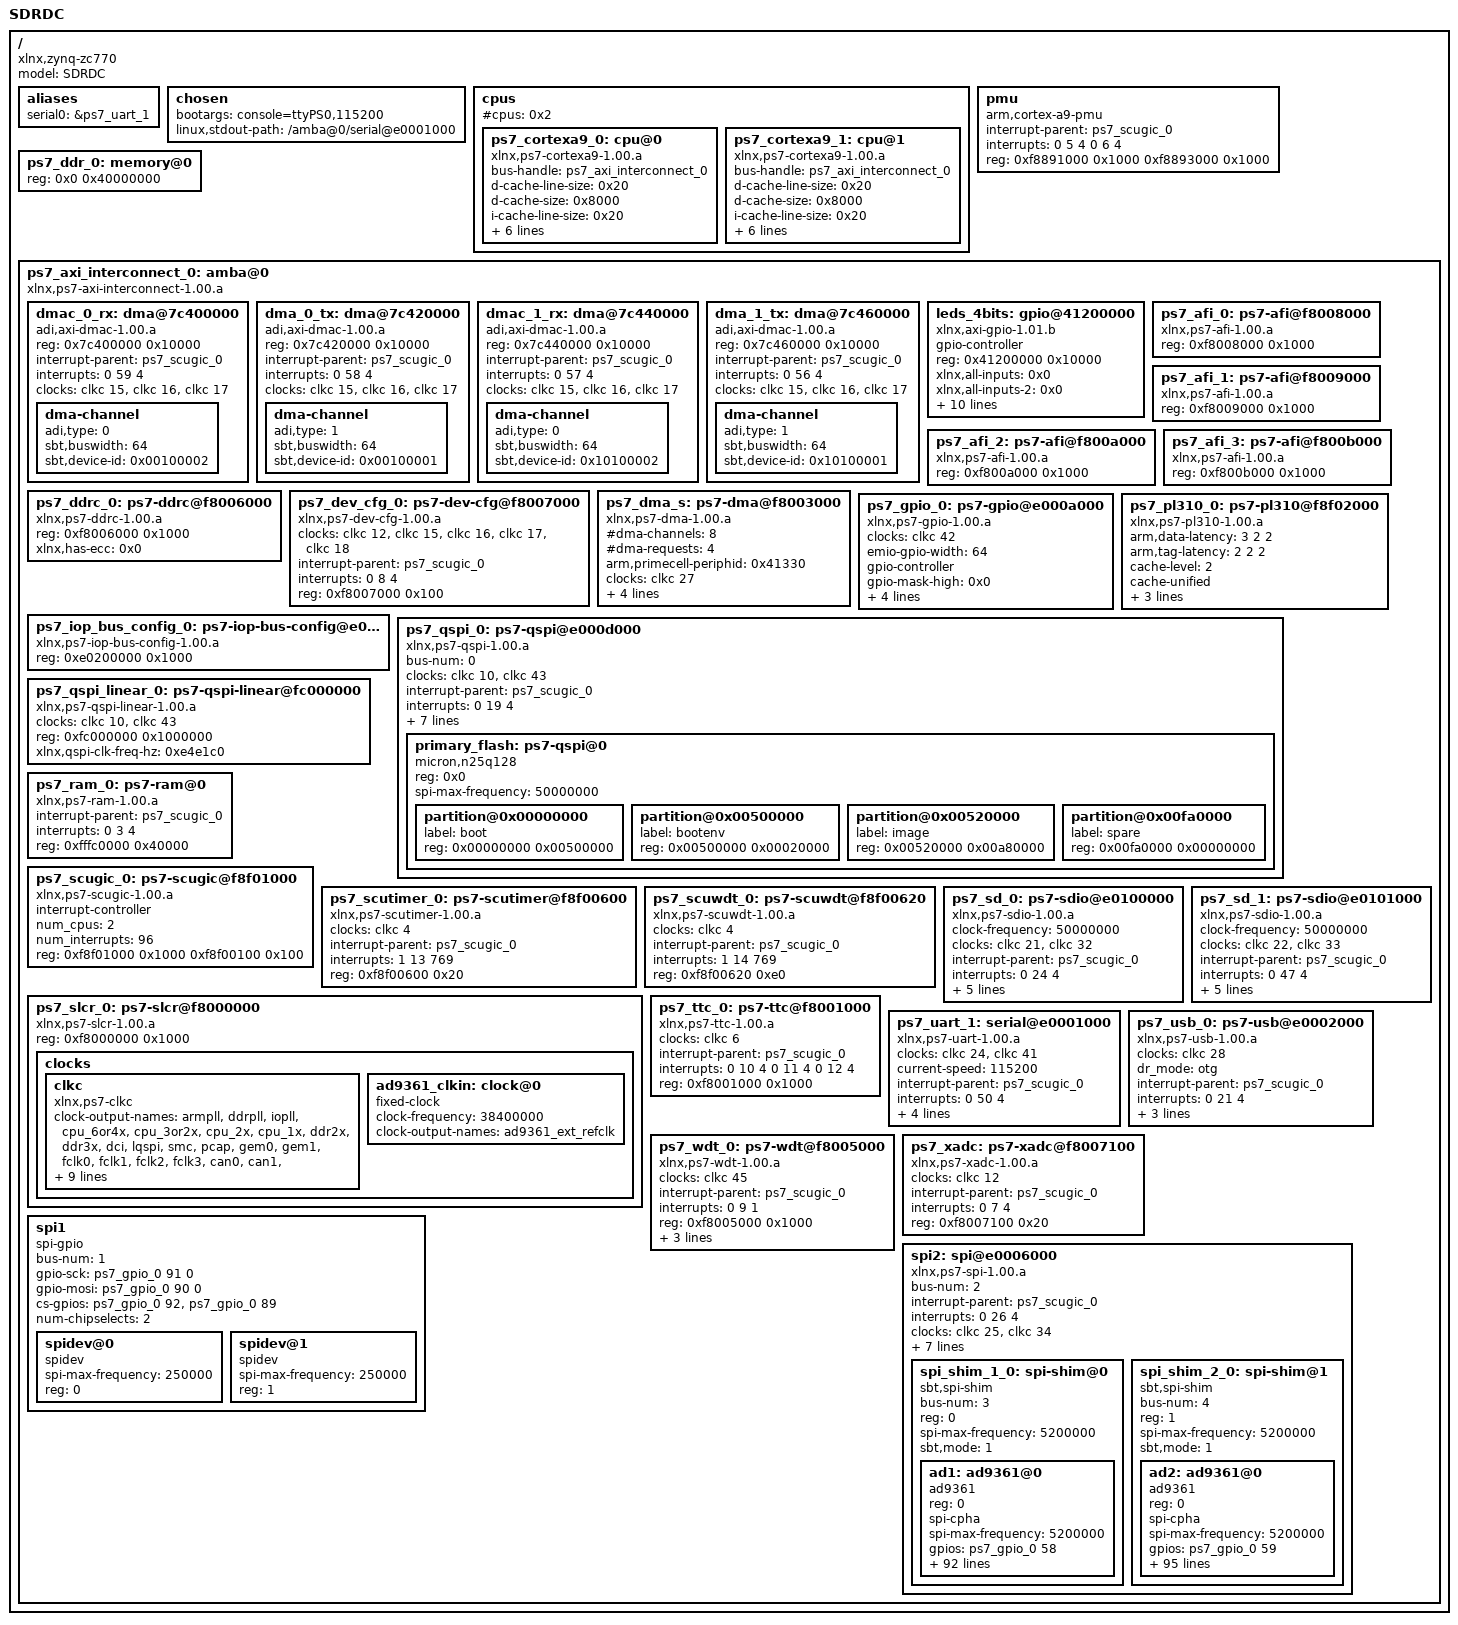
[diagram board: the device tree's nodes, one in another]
/*
 * Device Tree Generator version: 1.1
 *
 * (C) Copyright 2007-2012 Xilinx, Inc.
 * (C) Copyright 2007-2012 Michal Simek
 * (C) Copyright 2007-2012 PetaLogix Qld Pty Ltd
 *
 * Michal SIMEK <monstr@monstr.eu>
 *
 * This program is free software; you can redistribute it and/or
 * modify it under the terms of the GNU General Public License as
 * published by the Free Software Foundation; either version 2 of
 * the License, or (at your option) any later version.
 *
 * This program is distributed in the hope that it will be useful,
 * but WITHOUT ANY WARRANTY; without even the implied warranty of
 * MERCHANTABILITY or FITNESS FOR A PARTICULAR PURPOSE. See the
 * GNU General Public License for more details.
 *
 * You should have received a copy of the GNU General Public License
 * along with this program; if not, write to the Free Software
 * Foundation, Inc., 59 Temple Place, Suite 330, Boston,
 * MA 02111-1307 USA
 *
 * CAUTION: This file is automatically generated by libgen.
 * Version: Xilinx EDK 14.5 EDK_P.58f
 * Today is: Wednesday, the 27 of March, 2013; 04:30:06
 *
 * XPS project directory: Xilinx-ZC702-14.5
 */

/dts-v1/;
/ {
	#address-cells = <1>;
	#size-cells = <1>;
	compatible = "xlnx,zynq-zc770", "xlnx,zynq-7000";
	model = "SDRDC";
	aliases {
		serial0 = &ps7_uart_1;
	} ;
	chosen {
		bootargs = "console=ttyPS0,115200 ";
		linux,stdout-path = "/amba@0/serial@e0001000";
	} ;
	cpus {
		#address-cells = <1>;
		#cpus = <0x2>;
		#size-cells = <0>;
		ps7_cortexa9_0: cpu@0 {
			bus-handle = <&ps7_axi_interconnect_0>;
			compatible = "xlnx,ps7-cortexa9-1.00.a", "arm,cortex-a9";
			d-cache-line-size = <0x20>;
			d-cache-size = <0x8000>;
			device_type = "cpu";
			i-cache-line-size = <0x20>;
			i-cache-size = <0x8000>;
			model = "ps7_cortexa9,1.00.a";
			reg = <0>;
			xlnx,cpu-1x-clk-freq-hz = <0x69f6bca>;
			xlnx,cpu-clk-freq-hz = <0x27bc86c0>;
			interrupt-handle = <&ps7_scugic_0>;
		} ;
		ps7_cortexa9_1: cpu@1 {
			bus-handle = <&ps7_axi_interconnect_0>;
			compatible = "xlnx,ps7-cortexa9-1.00.a", "arm,cortex-a9";
			d-cache-line-size = <0x20>;
			d-cache-size = <0x8000>;
			device_type = "cpu";
			i-cache-line-size = <0x20>;
			i-cache-size = <0x8000>;
			model = "ps7_cortexa9,1.00.a";
			reg = <1>;
			xlnx,cpu-1x-clk-freq-hz = <0x69f6bca>;
			xlnx,cpu-clk-freq-hz = <0x27bc86c0>;
			interrupt-handle = <&ps7_scugic_0>;
		} ;
	} ;
	pmu {
		compatible = "arm,cortex-a9-pmu";
		interrupt-parent = <&ps7_scugic_0>;
		interrupts = < 0 5 4 0 6 4 >;
		reg = < 0xf8891000 0x1000 0xf8893000 0x1000 >;
		reg-names = "cpu0", "cpu1";
	} ;
	ps7_ddr_0: memory@0 {
		device_type = "memory";
		reg = < 0x0 0x40000000 >;
	} ;
	ps7_axi_interconnect_0: amba@0 {
		#address-cells = <1>;
		#size-cells = <1>;
		compatible = "xlnx,ps7-axi-interconnect-1.00.a", "simple-bus";
		ranges ;

		/* New DMAC from ADI git repo https://github.com/analogdevicesinc/linux.git */
		dmac_0_rx: dma@7c400000 {
			compatible = "adi,axi-dmac-1.00.a";
			reg = <0x7c400000 0x10000>;
			#dma-cells = <1>;
			interrupt-parent = <&ps7_scugic_0>;
			interrupts = <0 59 4>;
			clock-names = "fclk0", "fclk1", "fclk2";
			clocks = < &clkc 15 &clkc 16 &clkc 17 >;

			dma-channel {
				adi,type = <0>;
				sbt,buswidth = <64>;
				sbt,device-id = <0x00100002>;
			};
		};
		dma_0_tx: dma@7c420000 {
			compatible = "adi,axi-dmac-1.00.a";
			reg = <0x7c420000 0x10000>;
			#dma-cells = <1>;
			interrupt-parent = <&ps7_scugic_0>;
			interrupts = <0 58 4>;
			clock-names = "fclk0", "fclk1", "fclk2";
			clocks = < &clkc 15 &clkc 16 &clkc 17 >;

			dma-channel {
				adi,type = <1>;
				sbt,buswidth = <64>;
				sbt,device-id = <0x00100001>;
			};
		};
		dmac_1_rx: dma@7c440000 {
			compatible = "adi,axi-dmac-1.00.a";
			reg = <0x7c440000 0x10000>;
			#dma-cells = <1>;
			interrupt-parent = <&ps7_scugic_0>;
			interrupts = <0 57 4>;
			clock-names = "fclk0", "fclk1", "fclk2";
			clocks = < &clkc 15 &clkc 16 &clkc 17 >;

			dma-channel {
				adi,type = <0>;
				sbt,buswidth = <64>;
				sbt,device-id = <0x10100002>;
			};
		};
		dma_1_tx: dma@7c460000 {
			compatible = "adi,axi-dmac-1.00.a";
			reg = <0x7c460000 0x10000>;
			#dma-cells = <1>;
			interrupt-parent = <&ps7_scugic_0>;
			interrupts = <0 56 4>;
			clock-names = "fclk0", "fclk1", "fclk2";
			clocks = < &clkc 15 &clkc 16 &clkc 17 >;

			dma-channel {
				adi,type = <1>;
				sbt,buswidth = <64>;
				sbt,device-id = <0x10100001>;
			};
		};

		leds_4bits: gpio@41200000 {
			#gpio-cells = <2>;
			compatible = "xlnx,axi-gpio-1.01.b", "xlnx,xps-gpio-1.00.a";
			gpio-controller ;
			reg = < 0x41200000 0x10000 >;
			xlnx,all-inputs = <0x0>;
			xlnx,all-inputs-2 = <0x0>;
			xlnx,dout-default = <0x0>;
			xlnx,dout-default-2 = <0x0>;
			xlnx,family = "zynq";
			xlnx,gpio-width = <0x4>;
			xlnx,gpio2-width = <0x20>;
			xlnx,instance = "LEDs_4Bits";
			xlnx,interrupt-present = <0x0>;
			xlnx,is-dual = <0x0>;
			xlnx,tri-default = <0xffffffff>;
			xlnx,tri-default-2 = <0xffffffff>;
		} ;
		ps7_afi_0: ps7-afi@f8008000 {
			compatible = "xlnx,ps7-afi-1.00.a";
			reg = < 0xf8008000 0x1000 >;
		} ;
		ps7_afi_1: ps7-afi@f8009000 {
			compatible = "xlnx,ps7-afi-1.00.a";
			reg = < 0xf8009000 0x1000 >;
		} ;
		ps7_afi_2: ps7-afi@f800a000 {
			compatible = "xlnx,ps7-afi-1.00.a";
			reg = < 0xf800a000 0x1000 >;
		} ;
		ps7_afi_3: ps7-afi@f800b000 {
			compatible = "xlnx,ps7-afi-1.00.a";
			reg = < 0xf800b000 0x1000 >;
		} ;
		ps7_ddrc_0: ps7-ddrc@f8006000 {
			compatible = "xlnx,ps7-ddrc-1.00.a", "xlnx,ps7-ddrc";
			reg = < 0xf8006000 0x1000 >;
			xlnx,has-ecc = <0x0>;
		} ;
		ps7_dev_cfg_0: ps7-dev-cfg@f8007000 {
			clock-names = "ref_clk", "fclk0", "fclk1", "fclk2", "fclk3";
			clocks = <&clkc 12 &clkc 15 &clkc 16 &clkc 17 &clkc 18>;
			compatible = "xlnx,ps7-dev-cfg-1.00.a";
			interrupt-parent = <&ps7_scugic_0>;
			interrupts = < 0 8 4 >;
			reg = < 0xf8007000 0x100 >;
		} ;
		ps7_dma_s: ps7-dma@f8003000 {
			#dma-cells = <1>;
			#dma-channels = <8>;
			#dma-requests = <4>;
			arm,primecell-periphid = <0x41330>;
			clock-names = "apb_pclk";
			clocks = <&clkc 27>;
			compatible = "xlnx,ps7-dma-1.00.a", "arm,primecell", "arm,pl330";
			interrupt-names = "abort", "dma0", "dma1", "dma2", "dma3",
				"dma4", "dma5", "dma6", "dma7";
			interrupt-parent = <&ps7_scugic_0>;
			interrupts = < 0 13 4 0 14 4 0 15 4 0 16 4 0 17 4 0 40 4 0 41 4 0 42 4 0 43 4 >;
			reg = < 0xf8003000 0x1000 >;
		} ;
		ps7_gpio_0: ps7-gpio@e000a000 {
			#gpio-cells = <2>;
			clocks = <&clkc 42>;
			compatible = "xlnx,ps7-gpio-1.00.a";
			emio-gpio-width = <64>;
			gpio-controller ;
			gpio-mask-high = <0x0>;
			gpio-mask-low = <0x5600>;
			interrupt-parent = <&ps7_scugic_0>;
			interrupts = < 0 20 4 >;
			reg = < 0xe000a000 0x1000 >;
		} ;
		ps7_iop_bus_config_0: ps7-iop-bus-config@e0200000 {
			compatible = "xlnx,ps7-iop-bus-config-1.00.a";
			reg = < 0xe0200000 0x1000 >;
		} ;
		ps7_pl310_0: ps7-pl310@f8f02000 {
			arm,data-latency = < 3 2 2 >;
			arm,tag-latency = < 2 2 2 >;
			cache-level = < 2 >;
			cache-unified ;
			compatible = "xlnx,ps7-pl310-1.00.a", "arm,pl310-cache";
			interrupt-parent = <&ps7_scugic_0>;
			interrupts = < 0 2 4 >;
			reg = < 0xf8f02000 0x1000 >;
		} ;
		ps7_qspi_0: ps7-qspi@e000d000 {
			#address-cells = <1>;
			#size-cells = <0>;
			bus-num = <0>;
			clock-names = "ref_clk", "aper_clk";
			clocks = <&clkc 10 &clkc 43>;
			compatible = "xlnx,ps7-qspi-1.00.a";
			interrupt-parent = <&ps7_scugic_0>;
			interrupts = < 0 19 4 >;
			is-dual = <0>;
			num-chip-select = <1>;
			reg = < 0xe000d000 0x1000 >;
			speed-hz = <200000000>;
			xlnx,fb-clk = <0x1>;
			xlnx,qspi-clk-freq-hz = <0xbebc200>;
			xlnx,qspi-mode = <0x0>;
			primary_flash: ps7-qspi@0 {
				#address-cells = <1>;
				#size-cells = <1>;
				reg = < 0x0 >;
				spi-max-frequency = <50000000>;
				compatible = "micron,n25q128";
				partition@0x00000000 {
					label = "boot";
					reg = <0x00000000 0x00500000>;
				};
				partition@0x00500000 {
					label = "bootenv";
					reg = <0x00500000 0x00020000>;
				};
				partition@0x00520000 {
					label = "image";
					reg = <0x00520000 0x00a80000>;
				};
				partition@0x00fa0000 {
					label = "spare";
					reg = <0x00fa0000 0x00000000>;
				};
			} ;
		} ;
		ps7_qspi_linear_0: ps7-qspi-linear@fc000000 {
			clock-names = "ref_clk", "aper_clk";
			clocks = <&clkc 10 &clkc 43>;
			compatible = "xlnx,ps7-qspi-linear-1.00.a";
			reg = < 0xfc000000 0x1000000 >;
			xlnx,qspi-clk-freq-hz = <0xe4e1c0>;
		} ;
		ps7_ram_0: ps7-ram@0 {
			compatible = "xlnx,ps7-ram-1.00.a", "xlnx,ps7-ocm";
			interrupt-parent = <&ps7_scugic_0>;
			interrupts = < 0 3 4 >;
			reg = < 0xfffc0000 0x40000 >;
		} ;
		ps7_scugic_0: ps7-scugic@f8f01000 {
			#address-cells = < 2 >;
			#interrupt-cells = < 3 >;
			#size-cells = < 1 >;
			compatible = "xlnx,ps7-scugic-1.00.a", "arm,cortex-a9-gic", "arm,gic";
			interrupt-controller ;
			linux,phandle = < 0x1 >;
			phandle = < 0x1 >;
			num_cpus = <2>;
			num_interrupts = <96>;
			reg = < 0xf8f01000 0x1000 0xf8f00100 0x100 >;
		} ;
		ps7_scutimer_0: ps7-scutimer@f8f00600 {
			clocks = <&clkc 4>;
			compatible = "xlnx,ps7-scutimer-1.00.a", "arm,cortex-a9-twd-timer";
			interrupt-parent = <&ps7_scugic_0>;
			interrupts = < 1 13 769 >;
			reg = < 0xf8f00600 0x20 >;
		} ;
		ps7_scuwdt_0: ps7-scuwdt@f8f00620 {
			clocks = <&clkc 4>;
			compatible = "xlnx,ps7-scuwdt-1.00.a";
			device_type = "watchdog";
			interrupt-parent = <&ps7_scugic_0>;
			interrupts = < 1 14 769 >;
			reg = < 0xf8f00620 0xe0 >;
		} ;
		ps7_sd_0: ps7-sdio@e0100000 {
			clock-frequency = <50000000>;
			clock-names = "clk_xin", "clk_ahb";
			clocks = <&clkc 21 &clkc 32>;
			compatible = "xlnx,ps7-sdio-1.00.a", "generic-sdhci";
			interrupt-parent = <&ps7_scugic_0>;
			interrupts = < 0 24 4 >;
			reg = < 0xe0100000 0x1000 >;
			xlnx,has-cd = <0x0>;
			xlnx,has-power = <0x0>;
			xlnx,has-wp = <0x0>;
			xlnx,sdio-clk-freq-hz = <0x02FAF080>;
		} ;
		ps7_sd_1: ps7-sdio@e0101000 {
			clock-frequency = <50000000>;
			clock-names = "clk_xin", "clk_ahb";
			clocks = <&clkc 22 &clkc 33>;
			compatible = "xlnx,ps7-sdio-1.00.a", "generic-sdhci";
			interrupt-parent = <&ps7_scugic_0>;
			interrupts = < 0 47 4 >;
			reg = < 0xe0101000 0x1000 >;
			xlnx,has-cd = <0x0>;
			xlnx,has-power = <0x0>;
			xlnx,has-wp = <0x0>;
			xlnx,sdio-clk-freq-hz = <0x02FAF080>;
		} ;
		ps7_slcr_0: ps7-slcr@f8000000 {
			compatible = "xlnx,ps7-slcr-1.00.a", "xlnx,zynq-slcr";
			reg = < 0xf8000000 0x1000 >;
			clocks {
				#address-cells = <1>;
				#size-cells = <0>;
				clkc: clkc {
					#clock-cells = <1>;
					clock-output-names =
						"armpll",      /*  0 */
						"ddrpll",      /*  1 */
						"iopll",       /*  2 */
						"cpu_6or4x",   /*  3 */
						"cpu_3or2x",   /*  4 */
						"cpu_2x",      /*  5 */
						"cpu_1x",      /*  6 */
						"ddr2x",       /*  7 */
						"ddr3x",       /*  8 */
						"dci",         /*  9 */
						"lqspi",       /* 10 */
						"smc",         /* 11 */
						"pcap",        /* 12 */
						"gem0",        /* 13 */
						"gem1",        /* 14 */
						"fclk0",       /* 15 */
						"fclk1",       /* 16 */
						"fclk2",       /* 17 */
						"fclk3",       /* 18 */
						"can0",        /* 19 */
						"can1",        /* 20 */
						"sdio0",       /* 21 */
						"sdio1",       /* 22 */
						"uart0",       /* 23 */
						"uart1",       /* 24 */
						"spi0",        /* 25 */
						"spi1",        /* 26 */
						"dma",         /* 27 */
						"usb0_aper",   /* 28 */
						"usb1_aper",   /* 29 */
						"gem0_aper",   /* 30 */
						"gem1_aper",   /* 31 */
						"sdio0_aper",  /* 32 */
						"sdio1_aper",  /* 33 */
						"spi0_aper",   /* 34 */
						"spi1_aper",   /* 35 */
						"can0_aper",   /* 36 */
						"can1_aper",   /* 37 */
						"i2c0_aper",   /* 38 */
						"i2c1_aper",   /* 39 */
						"uart0_aper",  /* 40 */
						"uart1_aper",  /* 41 */
						"gpio_aper",   /* 42 */
						"lqspi_aper",  /* 43 */
						"smc_aper",    /* 44 */
						"swdt",        /* 45 */
						"dbg_trc",     /* 46 */
						"dbg_apb";     /* 47 */
					compatible = "xlnx,ps7-clkc";
					fclk-enable = <0xf>;
					ps-clk-frequency = <38400000>;
				} ;
				ad9361_clkin: clock@0 {
					#clock-cells = <0>;
					compatible = "fixed-clock";
					clock-frequency = <38400000>;
					clock-output-names = "ad9361_ext_refclk";
				};
			} ;
		} ;
		ps7_ttc_0: ps7-ttc@f8001000 {
			clocks = <&clkc 6>;
			compatible = "xlnx,ps7-ttc-1.00.a";
			interrupt-names = "ttc0", "ttc1", "ttc2";
			interrupt-parent = <&ps7_scugic_0>;
			interrupts = < 0 10 4 0 11 4 0 12 4 >;
			reg = < 0xf8001000 0x1000 >;
		} ;
		ps7_uart_1: serial@e0001000 {
			clock-names = "ref_clk", "aper_clk";
			clocks = <&clkc 24 &clkc 41>;
			compatible = "xlnx,ps7-uart-1.00.a", "xlnx,xuartps";
			current-speed = <115200>;
			device_type = "serial";
			interrupt-parent = <&ps7_scugic_0>;
			interrupts = < 0 50 4 >;
			port-number = <0>;
			reg = < 0xe0001000 0x1000 >;
			xlnx,has-modem = <0x0>;
			xlnx,uart-clk-freq-hz = <0x2faf080>;
		} ;
		ps7_usb_0: ps7-usb@e0002000 {
			clocks = <&clkc 28>;
			compatible = "xlnx,ps7-usb-1.00.a";
			dr_mode = "otg";
			interrupt-parent = <&ps7_scugic_0>;
			interrupts = < 0 21 4 >;
			phy_type = "ulpi";
			reg = < 0xe0002000 0x1000 >;
			xlnx,usb-reset = "MIO 7";
		} ;
		ps7_wdt_0: ps7-wdt@f8005000 {
			clocks = <&clkc 45>;
			compatible = "xlnx,ps7-wdt-1.00.a";
			device_type = "watchdog";
			interrupt-parent = <&ps7_scugic_0>;
			interrupts = < 0 9 1 >;
			reg = < 0xf8005000 0x1000 >;
			reset = <0>;
			timeout = <10>;
			xlnx,wdt-clk-freq-hz = <0x69f6bc8>;
		} ;
		ps7_xadc: ps7-xadc@f8007100 {
			clocks = <&clkc 12>;
			compatible = "xlnx,ps7-xadc-1.00.a";
			interrupt-parent = <&ps7_scugic_0>;
			interrupts = < 0 7 4 >;
			reg = < 0xf8007100 0x20 >;
		} ;

		spi1 {
			bus-num = <1>;
			compatible = "spi-gpio";
			#address-cells = <0x1>;
			ranges;

			gpio-sck  = < &ps7_gpio_0 91 0 >;
			gpio-mosi = < &ps7_gpio_0 90 0 >;
/*			gpio-miso = < &ps7_gpio_0 89 0 >; */
			cs-gpios  = <
				&ps7_gpio_0 92 0
				&ps7_gpio_0 89 0
			>;
			num-chipselects = <2>;

			spidev@0 {
				compatible = "spidev";
				spi-max-frequency = <250000>;
				reg = <0>;
			};
			spidev@1 {
				compatible = "spidev";
				spi-max-frequency = <250000>;
				reg = <1>;
			};
		};

		spi2: spi@e0006000 {
			bus-num = <2>;
			compatible = "xlnx,ps7-spi-1.00.a";
			interrupt-parent = <&ps7_scugic_0>;
			interrupts = <0 26 4>;
			clock-names = "ref_clk", "aper_clk";
			clocks = <&clkc 25>, <&clkc 34>;
			num-chip-select = <2>;
			reg = <0xe0006000 0x1000>;
			speed-hz = <166666666>;
			xlnx,has-ss0 = <0x1>;
			xlnx,has-ss1 = <0x1>;
			xlnx,has-ss2 = <0x0>;
			xlnx,spi-clk-freq-hz = <166666666>;
			#address-cells = <1>;
			#size-cells = <0>;

			spi_shim_1_0: spi-shim@0 {
				bus-num = <3>;
				compatible = "sbt,spi-shim", "spi-shim", "spi_shim";
				reg = <0>;
				spi-max-frequency = <5200000>;
				sbt,mode = <1>;

				/* Clients */
				ad1: ad9361@0 {
					#address-cells = <1>;
					#size-cells = <0>;
					#clock-cells = <1>;
					compatible = "ad9361";

					/* SPI Setup */
					reg = <0>;
					spi-cpha;
					spi-max-frequency = <5200000>;

					/* Reset: 58 (AD1), 59 (AD2)  */
					gpios = < &ps7_gpio_0 58 0 >;

					/* Enable: 104 (AD1), 111 (AD2) */
					/* TXNRX:  105 (AD1), 112 (AD2) */

					/* Clocks */
					clocks = <&ad9361_clkin 0>;
					clock-names = "ad9361_ext_refclk";
					clock-output-names = "rx_sampl_clk", "tx_sampl_clk";
					adi,clk-output-mode-select = <1>;

					//adi,debug-mode-enable;
					/* Digital Interface Control */

					adi,pp-tx-swap-enable;
					adi,pp-rx-swap-enable;
					adi,rx-frame-pulse-mode-enable;
					adi,lvds-mode-enable;
					adi,lvds-bias-mV = <225>;
					//adi,lvds-rx-onchip-termination-enable;
					adi,rx-data-delay = <11>;
					adi,tx-fb-clock-delay = <8>;
					adi,rx-data-clock-delay = <0>;
					adi,tx-data-delay = <0>;
					adi,full-port-enable;

					//adi,fdd-rx-rate-2tx-enable;

					adi,dcxo-coarse-and-fine-tune = <8 5920>;
					//adi,xo-disable-use-ext-refclk-enable;

					/* Mode Setup */
					adi,2rx-2tx-mode-enable;
					//adi,split-gain-table-mode-enable;

					/* Note: SDRDC DMA stack currently supports T2R2 mode only, regardless
					 * of how many channels are enabled.  leave this setting enabled if
					 * disabling adi,2rx-2tx-mode-enable above
					 */
					adi,2t2r-timing-enable;

					/* ENSM Mode */
					adi,frequency-division-duplex-mode-enable;
					//adi,ensm-pin-pulse-mode-enable;
					//adi,ensm-enable-txnrx-control-enable;


					/* adi,rx-rf-port-input-select:
					 * 0 = (RX1A_N &  RX1A_P) and (RX2A_N & RX2A_P) enabled; balanced
					 * 1 = (RX1B_N &  RX1B_P) and (RX2B_N & RX2B_P) enabled; balanced
					 * 2 = (RX1C_N &  RX1C_P) and (RX2C_N & RX2C_P) enabled; balanced
					 *
					 * 3 = RX1A_N and RX2A_N enabled; unbalanced
					 * 4 = RX1A_P and RX2A_P enabled; unbalanced
					 * 5 = RX1B_N and RX2B_N enabled; unbalanced
					 * 6 = RX1B_P and RX2B_P enabled; unbalanced
					 * 7 = RX1C_N and RX2C_N enabled; unbalanced
					 * 8 = RX1C_P and RX2C_P enabled; unbalanced
					 */

					adi,rx-rf-port-input-select = <0>; /* (RX1A_N &  RX1A_P) and (RX2A_N & RX2A_P) enabled; balanced */

					/* adi,tx-rf-port-input-select:
					 * 0	TX1A, TX2A
					 * 1	TX1B, TX2B
					 */

					adi,tx-rf-port-input-select = <0>; /* TX1A, TX2A */
					//adi,update-tx-gain-in-alert-enable;
					adi,tx-attenuation-mdB = <10000>;

					adi,rf-rx-bandwidth-hz = <3500000>;
					adi,rf-tx-bandwidth-hz = <3500000>;
					adi,rx-synthesizer-frequency-hz = /bits/ 64 <2400000000>;
					adi,tx-synthesizer-frequency-hz = /bits/ 64 <2400000000>;

					/*                              BBPLL        ADC        R2CLK     R1CLK     CLKRF    RSAMPL  */
					adi,rx-path-clock-frequencies = <1024000000  128000000  32000000  16000000  4000000  4000000>;
					/*                              BBPLL        DAC        T2CLK     T1CLK     CLKTF    TSAMPL  */
					adi,tx-path-clock-frequencies = <1024000000  128000000  32000000  16000000  4000000  4000000>;

					/* Gain Control */

					/* adi,gc-rx[1|2]-mode:
					 * 0 = RF_GAIN_MGC
					 * 1 = RF_GAIN_FASTATTACK_AGC
					 * 2 = RF_GAIN_SLOWATTACK_AGC
					 * 3 = RF_GAIN_HYBRID_AGC
					 */

					adi,gc-rx1-mode = <1>;
					adi,gc-rx2-mode = <1>;
					adi,gc-adc-ovr-sample-size = <4>; /* sum 4 samples */
					adi,gc-adc-small-overload-thresh = <47>; /* sum of squares */
					adi,gc-adc-large-overload-thresh = <58>; /* sum of squares */
					adi,gc-lmt-overload-high-thresh = <800>; /* mV */
					adi,gc-lmt-overload-low-thresh = <704>; /* mV */
					adi,gc-dec-pow-measurement-duration = <8192>; /* 0..524288 Samples */
					adi,gc-low-power-thresh = <24>; /* 0..-64 dBFS vals are set pos */
					//adi,gc-dig-gain-enable;
					//adi,gc-max-dig-gain = <15>;

					/* Manual Gain Control Setup */

					//adi,mgc-rx1-ctrl-inp-enable; /* uncomment to use ctrl inputs */
					//adi,mgc-rx2-ctrl-inp-enable; /* uncomment to use ctrl inputs */
					adi,mgc-inc-gain-step = <2>;
					adi,mgc-dec-gain-step = <2>;

					/* adi,mgc-split-table-ctrl-inp-gain-mode:
					 * (relevant if adi,split-gain-table-mode-enable is set)
					 * 0 = AGC determine this
					 * 1 = only in LPF
					 * 2 = only in LMT
					 */

					adi,mgc-split-table-ctrl-inp-gain-mode = <0>;

					/* Automatic Gain Control Setup */

					adi,agc-attack-delay-extra-margin-us= <1>; /* us */
					adi,agc-outer-thresh-high = <5>; /* -dBFS */
					adi,agc-outer-thresh-high-dec-steps = <2>; /* 0..15 */
					adi,agc-inner-thresh-high = <10>; /* -dBFS */
					adi,agc-inner-thresh-high-dec-steps = <1>; /* 0..7 */
					adi,agc-inner-thresh-low = <12>; /* -dBFS */
					adi,agc-inner-thresh-low-inc-steps = <1>; /* 0..7 */
					adi,agc-outer-thresh-low = <18>; /* -dBFS */
					adi,agc-outer-thresh-low-inc-steps = <2>; /* 0..15 */

					adi,agc-adc-small-overload-exceed-counter = <10>; /* 0..15 */
					adi,agc-adc-large-overload-exceed-counter = <10>; /* 0..15 */
					adi,agc-adc-large-overload-inc-steps = <2>; /* 0..15 */
					//adi,agc-adc-lmt-small-overload-prevent-gain-inc-enable;
					adi,agc-lmt-overload-large-exceed-counter = <10>; /* 0..15 */
					adi,agc-lmt-overload-small-exceed-counter = <10>; /* 0..15 */
					adi,agc-lmt-overload-large-inc-steps = <2>; /* 0..7 */
					//adi,agc-dig-saturation-exceed-counter = <3>; /* 0..15 */
					//adi,agc-dig-gain-step-size = <4>; /* 1..8 */

					//adi,agc-sync-for-gain-counter-enable;
					adi,agc-gain-update-interval-us = <1000>;  /* 1ms */
					//adi,agc-immed-gain-change-if-large-adc-overload-enable;
					//adi,agc-immed-gain-change-if-large-lmt-overload-enable;

					/* Fast AGC */

					//adi,fagc-allow-agc-gain-increase-enable;
					adi,fagc-lp-thresh-increment-steps = <1>;
					adi,fagc-lp-thresh-increment-time = <5>;

					adi,fagc-energy-lost-stronger-sig-gain-lock-exit-cnt = <8>;
					adi,fagc-final-overrange-count = <3>;
					//adi,fagc-gain-increase-after-gain-lock-enable;
					adi,fagc-gain-index-type-after-exit-rx-mode = <0>;
					adi,fagc-lmt-final-settling-steps = <1>;
					adi,fagc-lock-level = <10>;
					adi,fagc-lock-level-gain-increase-upper-limit = <5>;
					adi,fagc-lock-level-lmt-gain-increase-enable;

					adi,fagc-lpf-final-settling-steps = <1>;
					adi,fagc-optimized-gain-offset = <5>;
					adi,fagc-power-measurement-duration-in-state5 = <64>;
					adi,fagc-rst-gla-engergy-lost-goto-optim-gain-enable;
					adi,fagc-rst-gla-engergy-lost-sig-thresh-below-ll = <10>;
					adi,fagc-rst-gla-engergy-lost-sig-thresh-exceeded-enable;
					adi,fagc-rst-gla-if-en-agc-pulled-high-mode = <0>;
					adi,fagc-rst-gla-large-adc-overload-enable;
					adi,fagc-rst-gla-large-lmt-overload-enable;
					adi,fagc-rst-gla-stronger-sig-thresh-above-ll = <10>;
					adi,fagc-rst-gla-stronger-sig-thresh-exceeded-enable;
					adi,fagc-state-wait-time-ns = <260>;
					adi,fagc-use-last-lock-level-for-set-gain-enable;

					/* RSSI */

					/* adi,rssi-restart-mode:
					 * 0 = AGC_IN_FAST_ATTACK_MODE_LOCKS_THE_GAIN,
					 * 1 = EN_AGC_PIN_IS_PULLED_HIGH,
					 * 2 = ENTERS_RX_MODE,
					 * 3 = GAIN_CHANGE_OCCURS,
					 * 4 = SPI_WRITE_TO_REGISTER,
					 * 5 = GAIN_CHANGE_OCCURS_OR_EN_AGC_PIN_PULLED_HIGH,
					 */
					adi,rssi-restart-mode = <3>;
					//adi,rssi-unit-is-rx-samples-enable;
					adi,rssi-delay = <1>; /* 1us */
					adi,rssi-wait = <1>; /* 1us */
					adi,rssi-duration = <1000>; /* 1ms */

					/* Control Outputs */
					adi,ctrl-outs-index = <0>;
					adi,ctrl-outs-enable-mask = <0xFF>;

					/* AuxADC Temp Sense Control */

					adi,temp-sense-measurement-interval-ms = <1000>;
					adi,temp-sense-offset-signed = <0xCE>;
					adi,temp-sense-periodic-measurement-enable;

				}; // ad1

			}; // spi_shim_1_0

			spi_shim_2_0: spi-shim@1 {
				bus-num = <4>;
				compatible = "sbt,spi-shim", "spi-shim", "spi_shim";
				reg = <1>;
				spi-max-frequency = <5200000>;
				sbt,mode = <1>;

				/* clients */
				ad2: ad9361@0 {
					#address-cells = <1>;
					#size-cells = <0>;
					#clock-cells = <1>;
					compatible = "ad9361";

					/* SPI Setup */
					reg = <0>;
					spi-cpha;
					spi-max-frequency = <5200000>;

					/* Reset: 58 (AD1), 59 (AD2)  */
					gpios = < &ps7_gpio_0 59 0 >;

					/* Enable: 104 (AD1), 111 (AD2) */
					/* TXNRX:  105 (AD1), 112 (AD2) */

					/* Clocks */
					clocks = <&ad9361_clkin 0>;
					clock-names = "ad9361_ext_refclk";
					clock-output-names = "rx_sampl_clk", "tx_sampl_clk";
					adi,clk-output-mode-select = <1>;

					//adi,debug-mode-enable;
					/* Digital Interface Control */

					adi,pp-tx-swap-enable;
					adi,pp-rx-swap-enable;
					adi,rx-frame-pulse-mode-enable;
					adi,lvds-mode-enable;
					adi,lvds-bias-mV = <225>;
					//adi,lvds-rx-onchip-termination-enable;
					adi,rx-data-delay = <11>;
					adi,tx-fb-clock-delay = <8>;
					adi,rx-data-clock-delay = <0>;
					adi,tx-data-delay = <0>;
					adi,full-port-enable;

					//adi,fdd-rx-rate-2tx-enable;

					adi,dcxo-coarse-and-fine-tune = <8 5920>;
					//adi,xo-disable-use-ext-refclk-enable;

					/* Mode Setup */
					adi,2rx-2tx-mode-enable;
					//adi,split-gain-table-mode-enable;

					/* Note: SDRDC DMA stack currently supports T2R2 mode only, regardless
					 * of how many channels are enabled.  leave this setting enabled if
					 * disabling adi,2rx-2tx-mode-enable above
					 */
					adi,2t2r-timing-enable;

					/* ENSM Mode */
					adi,frequency-division-duplex-mode-enable;
					//adi,ensm-pin-pulse-mode-enable;
					//adi,ensm-enable-txnrx-control-enable;


					/* adi,rx-rf-port-input-select:
					 * 0 = (RX1A_N &  RX1A_P) and (RX2A_N & RX2A_P) enabled; balanced
					 * 1 = (RX1B_N &  RX1B_P) and (RX2B_N & RX2B_P) enabled; balanced
					 * 2 = (RX1C_N &  RX1C_P) and (RX2C_N & RX2C_P) enabled; balanced
					 *
					 * 3 = RX1A_N and RX2A_N enabled; unbalanced
					 * 4 = RX1A_P and RX2A_P enabled; unbalanced
					 * 5 = RX1B_N and RX2B_N enabled; unbalanced
					 * 6 = RX1B_P and RX2B_P enabled; unbalanced
					 * 7 = RX1C_N and RX2C_N enabled; unbalanced
					 * 8 = RX1C_P and RX2C_P enabled; unbalanced
					 */

					adi,rx-rf-port-input-select = <0>; /* (RX1A_N &  RX1A_P) and (RX2A_N & RX2A_P) enabled; balanced */

					/* adi,tx-rf-port-input-select:
					 * 0	TX1A, TX2A
					 * 1	TX1B, TX2B
					 */

					adi,tx-rf-port-input-select = <0>; /* TX1A, TX2A */
					//adi,update-tx-gain-in-alert-enable;
					adi,tx-attenuation-mdB = <10000>;

					adi,rf-rx-bandwidth-hz = <3500000>;
					adi,rf-tx-bandwidth-hz = <3500000>;
					adi,rx-synthesizer-frequency-hz = /bits/ 64 <2400000000>;
					adi,tx-synthesizer-frequency-hz = /bits/ 64 <2400000000>;

					/*                              BBPLL        ADC        R2CLK     R1CLK     CLKRF    RSAMPL  */
					adi,rx-path-clock-frequencies = <1024000000  128000000  32000000  16000000  4000000  4000000>;
					/*                              BBPLL        DAC        T2CLK     T1CLK     CLKTF    TSAMPL  */
					adi,tx-path-clock-frequencies = <1024000000  128000000  32000000  16000000  4000000  4000000>;

					/* Gain Control */

					/* adi,gc-rx[1|2]-mode:
					 * 0 = RF_GAIN_MGC
					 * 1 = RF_GAIN_FASTATTACK_AGC
					 * 2 = RF_GAIN_SLOWATTACK_AGC
					 * 3 = RF_GAIN_HYBRID_AGC
					 */

					adi,gc-rx1-mode = <1>;
					adi,gc-rx2-mode = <1>;
					adi,gc-adc-ovr-sample-size = <4>; /* sum 4 samples */
					adi,gc-adc-small-overload-thresh = <47>; /* sum of squares */
					adi,gc-adc-large-overload-thresh = <58>; /* sum of squares */
					adi,gc-lmt-overload-high-thresh = <800>; /* mV */
					adi,gc-lmt-overload-low-thresh = <704>; /* mV */
					adi,gc-dec-pow-measurement-duration = <8192>; /* 0..524288 Samples */
					adi,gc-low-power-thresh = <24>; /* 0..-64 dBFS vals are set pos */
					//adi,gc-dig-gain-enable;
					//adi,gc-max-dig-gain = <15>;

					/* Manual Gain Control Setup */

					//adi,mgc-rx1-ctrl-inp-enable; /* uncomment to use ctrl inputs */
					//adi,mgc-rx2-ctrl-inp-enable; /* uncomment to use ctrl inputs */
					adi,mgc-inc-gain-step = <2>;
					adi,mgc-dec-gain-step = <2>;

					/* adi,mgc-split-table-ctrl-inp-gain-mode:
					 * (relevant if adi,split-gain-table-mode-enable is set)
					 * 0 = AGC determine this
					 * 1 = only in LPF
					 * 2 = only in LMT
					 */

					adi,mgc-split-table-ctrl-inp-gain-mode = <0>;

					/* Automatic Gain Control Setup */

					adi,agc-attack-delay-extra-margin-us= <1>; /* us */
					adi,agc-outer-thresh-high = <5>; /* -dBFS */
					adi,agc-outer-thresh-high-dec-steps = <2>; /* 0..15 */
					adi,agc-inner-thresh-high = <10>; /* -dBFS */
					adi,agc-inner-thresh-high-dec-steps = <1>; /* 0..7 */
					adi,agc-inner-thresh-low = <12>; /* -dBFS */
					adi,agc-inner-thresh-low-inc-steps = <1>; /* 0..7 */
					adi,agc-outer-thresh-low = <18>; /* -dBFS */
					adi,agc-outer-thresh-low-inc-steps = <2>; /* 0..15 */

					adi,agc-adc-small-overload-exceed-counter = <10>; /* 0..15 */
					adi,agc-adc-large-overload-exceed-counter = <10>; /* 0..15 */
					adi,agc-adc-large-overload-inc-steps = <2>; /* 0..15 */
					//adi,agc-adc-lmt-small-overload-prevent-gain-inc-enable;
					adi,agc-lmt-overload-large-exceed-counter = <10>; /* 0..15 */
					adi,agc-lmt-overload-small-exceed-counter = <10>; /* 0..15 */
					adi,agc-lmt-overload-large-inc-steps = <2>; /* 0..7 */
					//adi,agc-dig-saturation-exceed-counter = <3>; /* 0..15 */
					//adi,agc-dig-gain-step-size = <4>; /* 1..8 */

					//adi,agc-sync-for-gain-counter-enable;
					adi,agc-gain-update-interval-us = <1000>;  /* 1ms */
					//adi,agc-immed-gain-change-if-large-adc-overload-enable;
					//adi,agc-immed-gain-change-if-large-lmt-overload-enable;

					/* Fast AGC */

					//adi,fagc-allow-agc-gain-increase-enable;
					adi,fagc-lp-thresh-increment-steps = <1>;
					adi,fagc-lp-thresh-increment-time = <5>;

					adi,fagc-energy-lost-stronger-sig-gain-lock-exit-cnt = <8>;
					adi,fagc-final-overrange-count = <3>;
					//adi,fagc-gain-increase-after-gain-lock-enable;
					adi,fagc-gain-index-type-after-exit-rx-mode = <0>;
					adi,fagc-lmt-final-settling-steps = <1>;
					adi,fagc-lock-level = <10>;
					adi,fagc-lock-level-gain-increase-upper-limit = <5>;
					adi,fagc-lock-level-lmt-gain-increase-enable;

					adi,fagc-lpf-final-settling-steps = <1>;
					adi,fagc-optimized-gain-offset = <5>;
					adi,fagc-power-measurement-duration-in-state5 = <64>;
					adi,fagc-rst-gla-engergy-lost-goto-optim-gain-enable;
					adi,fagc-rst-gla-engergy-lost-sig-thresh-below-ll = <10>;
					adi,fagc-rst-gla-engergy-lost-sig-thresh-exceeded-enable;
					adi,fagc-rst-gla-if-en-agc-pulled-high-mode = <0>;
					adi,fagc-rst-gla-large-adc-overload-enable;
					adi,fagc-rst-gla-large-lmt-overload-enable;
					adi,fagc-rst-gla-stronger-sig-thresh-above-ll = <10>;
					adi,fagc-rst-gla-stronger-sig-thresh-exceeded-enable;
					adi,fagc-state-wait-time-ns = <260>;
					adi,fagc-use-last-lock-level-for-set-gain-enable;

					/* RSSI */

					/* adi,rssi-restart-mode:
					 * 0 = AGC_IN_FAST_ATTACK_MODE_LOCKS_THE_GAIN,
					 * 1 = EN_AGC_PIN_IS_PULLED_HIGH,
					 * 2 = ENTERS_RX_MODE,
					 * 3 = GAIN_CHANGE_OCCURS,
					 * 4 = SPI_WRITE_TO_REGISTER,
					 * 5 = GAIN_CHANGE_OCCURS_OR_EN_AGC_PIN_PULLED_HIGH,
					 */
					adi,rssi-restart-mode = <3>;
					//adi,rssi-unit-is-rx-samples-enable;
					adi,rssi-delay = <1>; /* 1us */
					adi,rssi-wait = <1>; /* 1us */
					adi,rssi-duration = <1000>; /* 1ms */

					/* Control Outputs */
					adi,ctrl-outs-index = <0>;
					adi,ctrl-outs-enable-mask = <0xFF>;

					/* AuxADC Temp Sense Control */

					adi,temp-sense-measurement-interval-ms = <1000>;
					adi,temp-sense-offset-signed = <0xCE>;
					adi,temp-sense-periodic-measurement-enable;

					/* Aux DAC is used for XO tuning on SDRDC */
					adi,aux-dac-manual-mode-enable;
					adi,aux-dac1-default-value-mV = <1430>;
					adi,aux-dac2-default-value-mV = <1430>;

				}; // ad2

			}; // spi_shim_2_0

		}; // spi2
	} ;
} ;
